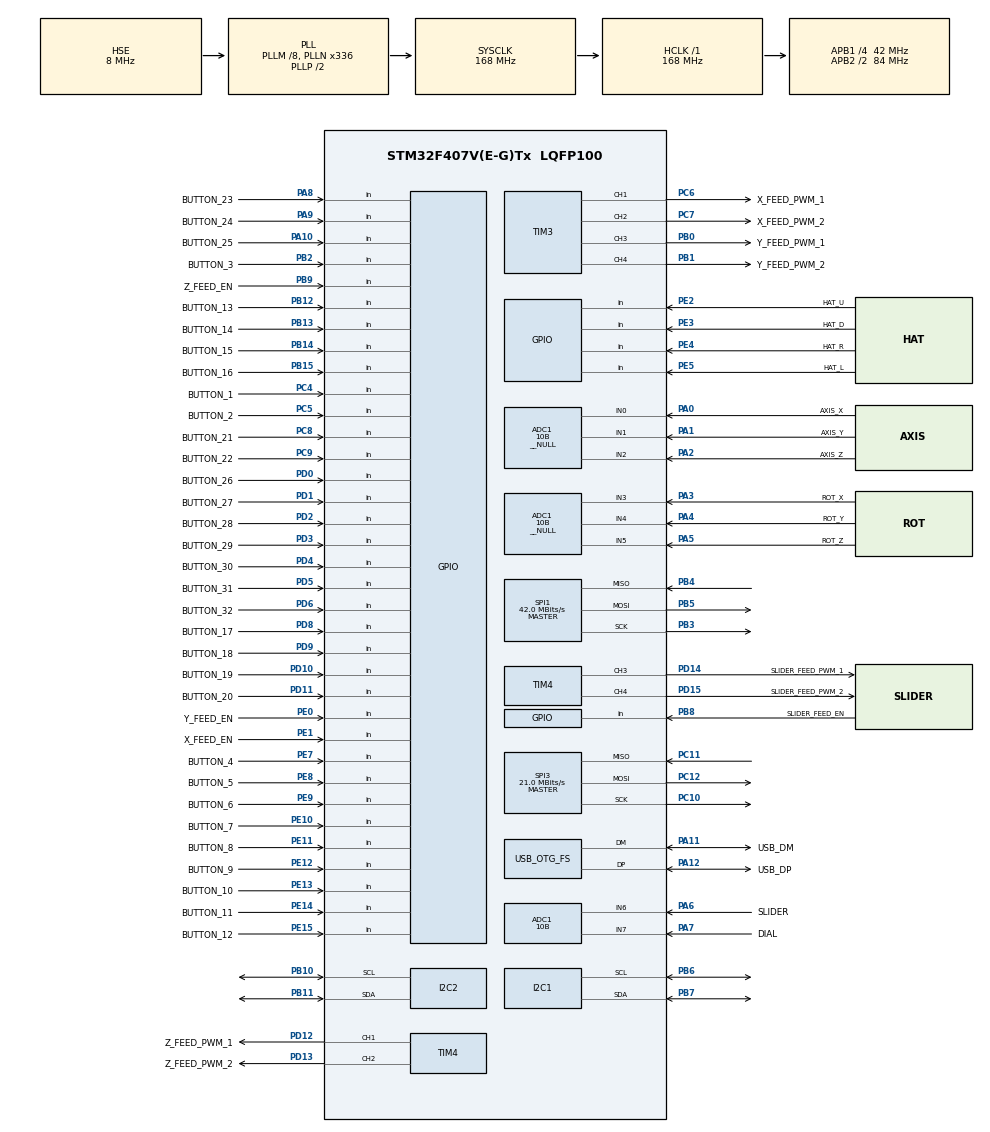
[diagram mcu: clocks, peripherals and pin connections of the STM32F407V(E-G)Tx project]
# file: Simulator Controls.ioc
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ADC1.Channel-0\#ChannelRegularConversion=ADC_CHANNEL_0
ADC1.Channel-1\#ChannelRegularConversion=ADC_CHANNEL_1
ADC1.Channel-2\#ChannelRegularConversion=ADC_CHANNEL_2
ADC1.Channel-3\#ChannelRegularConversion=ADC_CHANNEL_3
ADC1.Channel-4\#ChannelRegularConversion=ADC_CHANNEL_4
ADC1.Channel-5\#ChannelRegularConversion=ADC_CHANNEL_5
ADC1.Channel-6\#ChannelRegularConversion=ADC_CHANNEL_6
ADC1.Channel-7\#ChannelRegularConversion=ADC_CHANNEL_7
ADC1.ClockPrescaler=ADC_CLOCK_SYNC_PCLK_DIV4
ADC1.ContinuousConvMode=ENABLE
ADC1.DMAContinuousRequests=ENABLE
ADC1.DataAlign=ADC_DATAALIGN_RIGHT
ADC1.DiscontinuousConvMode=DISABLE
ADC1.EOCSelection=ADC_EOC_SEQ_CONV
ADC1.EnableAnalogWatchDog=false
ADC1.ExternalTrigConvEdge=ADC_EXTERNALTRIGCONVEDGE_NONE
ADC1.InjNumberOfConversion=0
ADC1.Mode=__NULL
ADC1.NbrOfConversion=8
ADC1.NbrOfConversionFlag=1
ADC1.Rank-0\#ChannelRegularConversion=1
ADC1.Rank-1\#ChannelRegularConversion=2
ADC1.Rank-2\#ChannelRegularConversion=3
ADC1.Rank-3\#ChannelRegularConversion=4
ADC1.Rank-4\#ChannelRegularConversion=5
ADC1.Rank-5\#ChannelRegularConversion=6
ADC1.Rank-6\#ChannelRegularConversion=7
ADC1.Rank-7\#ChannelRegularConversion=8
ADC1.Resolution=ADC_RESOLUTION_10B
ADC1.SamplingTime-0\#ChannelRegularConversion=ADC_SAMPLETIME_480CYCLES
ADC1.SamplingTime-1\#ChannelRegularConversion=ADC_SAMPLETIME_480CYCLES
ADC1.SamplingTime-2\#ChannelRegularConversion=ADC_SAMPLETIME_480CYCLES
ADC1.SamplingTime-3\#ChannelRegularConversion=ADC_SAMPLETIME_480CYCLES
ADC1.SamplingTime-4\#ChannelRegularConversion=ADC_SAMPLETIME_480CYCLES
ADC1.SamplingTime-5\#ChannelRegularConversion=ADC_SAMPLETIME_480CYCLES
ADC1.SamplingTime-6\#ChannelRegularConversion=ADC_SAMPLETIME_480CYCLES
ADC1.SamplingTime-7\#ChannelRegularConversion=ADC_SAMPLETIME_480CYCLES
ADC1.ScanConvMode=ENABLE
ADC1.master=1
Dma.ADC1.0.Direction=DMA_PERIPH_TO_MEMORY
Dma.ADC1.0.FIFOMode=DMA_FIFOMODE_DISABLE
Dma.ADC1.0.Instance=DMA2_Stream0
Dma.ADC1.0.MemDataAlignment=DMA_MDATAALIGN_WORD
Dma.ADC1.0.MemInc=DMA_MINC_ENABLE
Dma.ADC1.0.Mode=DMA_CIRCULAR
Dma.ADC1.0.PeriphDataAlignment=DMA_PDATAALIGN_WORD
Dma.ADC1.0.PeriphInc=DMA_PINC_DISABLE
Dma.ADC1.0.Priority=DMA_PRIORITY_LOW
Dma.Request0=ADC1
Mcu.Family=STM32F4
Mcu.Name=STM32F407V(E-G)Tx
Mcu.Package=LQFP100
NVIC.DMA2_Stream0_IRQn=true\:0\:0\:false\:false\:true
NVIC.OTG_FS_IRQn=true\:0\:0\:false\:false\:true
NVIC.PriorityGroup=NVIC_PRIORITYGROUP_4
PA0-WKUP.GPIO_Label=AXIS_X
PA0-WKUP.Signal=ADCx_IN0
PA1.GPIO_Label=AXIS_Y
PA1.Signal=ADCx_IN1
PA10.GPIO_Label=BUTTON_25
PA10.GPIO_Mode=GPIO_MODE_INPUT
PA10.GPIO_PuPd=GPIO_PULLDOWN
PA10.Signal=GPIO_Input
PA11.GPIO_Label=USB_DM
PA11.Mode=Device_Only
PA11.Signal=USB_OTG_FS_DM
PA12.GPIO_Label=USB_DP
PA12.Mode=Device_Only
PA12.Signal=USB_OTG_FS_DP
PA13.GPIO_Label=SWDIO
PA13.Mode=Serial_Wire
PA13.Signal=SYS_JTMS-SWDIO
PA14.GPIO_Label=SWCLK
PA14.Mode=Serial_Wire
PA14.Signal=SYS_JTCK-SWCLK
PA2.GPIO_Label=AXIS_Z
PA2.Signal=ADCx_IN2
PA3.GPIO_Label=ROT_X
PA3.Signal=ADCx_IN3
PA4.GPIO_Label=ROT_Y
PA4.Signal=ADCx_IN4
PA5.GPIO_Label=ROT_Z
PA5.Signal=ADCx_IN5
PA6.GPIO_Label=SLIDER
PA6.Signal=ADCx_IN6
PA7.GPIO_Label=DIAL
PA7.Signal=ADCx_IN7
PA8.GPIO_Label=BUTTON_23
PA8.GPIO_Mode=GPIO_MODE_INPUT
PA8.GPIO_PuPd=GPIO_PULLDOWN
PA8.Signal=GPIO_Input
PA9.GPIO_Label=BUTTON_24
PA9.GPIO_Mode=GPIO_MODE_INPUT
PA9.GPIO_PuPd=GPIO_PULLDOWN
PA9.Signal=GPIO_Input
PB0.GPIO_Label=Y_FEED_PWM_1
PB0.Signal=S_TIM3_CH3
PB1.GPIO_Label=Y_FEED_PWM_2
PB1.Signal=S_TIM3_CH4
PB10.Mode=I2C
PB10.Signal=I2C2_SCL
PB11.Mode=I2C
PB11.Signal=I2C2_SDA
PB12.GPIO_Label=BUTTON_13
PB12.GPIO_Mode=GPIO_MODE_INPUT
PB12.GPIO_PuPd=GPIO_PULLDOWN
PB12.Signal=GPIO_Input
PB13.GPIO_Label=BUTTON_14
PB13.GPIO_Mode=GPIO_MODE_INPUT
PB13.GPIO_PuPd=GPIO_PULLDOWN
PB13.Signal=GPIO_Input
PB14.GPIO_Label=BUTTON_15
PB14.GPIO_Mode=GPIO_MODE_INPUT
PB14.GPIO_PuPd=GPIO_PULLDOWN
PB14.Signal=GPIO_Input
PB15.GPIO_Label=BUTTON_16
PB15.GPIO_Mode=GPIO_MODE_INPUT
PB15.GPIO_PuPd=GPIO_PULLDOWN
PB15.Signal=GPIO_Input
PB2.GPIO_Label=BUTTON_3
PB2.GPIO_Mode=GPIO_MODE_INPUT
PB2.GPIO_PuPd=GPIO_PULLDOWN
PB2.Signal=GPIO_Input
PB3.Mode=Full_Duplex_Master
PB3.Signal=SPI1_SCK
PB4.Mode=Full_Duplex_Master
PB4.Signal=SPI1_MISO
PB5.Mode=Full_Duplex_Master
PB5.Signal=SPI1_MOSI
PB6.Mode=I2C
PB6.Signal=I2C1_SCL
PB7.Mode=I2C
PB7.Signal=I2C1_SDA
PB8.GPIO_Label=SLIDER_FEED_EN
PB8.GPIO_Mode=GPIO_MODE_INPUT
PB8.GPIO_PuPd=GPIO_PULLDOWN
PB8.Signal=GPIO_Input
PB9.GPIO_Label=Z_FEED_EN
PB9.GPIO_Mode=GPIO_MODE_INPUT
PB9.GPIO_PuPd=GPIO_PULLDOWN
PB9.Signal=GPIO_Input
PC10.Mode=Full_Duplex_Master
PC10.Signal=SPI3_SCK
PC11.Mode=Full_Duplex_Master
PC11.Signal=SPI3_MISO
PC12.Mode=Full_Duplex_Master
PC12.Signal=SPI3_MOSI
PC4.GPIO_Label=BUTTON_1
PC4.GPIO_Mode=GPIO_MODE_INPUT
PC4.GPIO_PuPd=GPIO_PULLDOWN
PC4.Signal=GPIO_Input
PC5.GPIO_Label=BUTTON_2
PC5.GPIO_Mode=GPIO_MODE_INPUT
PC5.GPIO_PuPd=GPIO_PULLDOWN
PC5.Signal=GPIO_Input
PC6.GPIO_Label=X_FEED_PWM_1
PC6.Signal=S_TIM3_CH1
PC7.GPIO_Label=X_FEED_PWM_2
PC7.Signal=S_TIM3_CH2
PC8.GPIO_Label=BUTTON_21
PC8.GPIO_Mode=GPIO_MODE_INPUT
PC8.GPIO_PuPd=GPIO_PULLDOWN
PC8.Signal=GPIO_Input
PC9.GPIO_Label=BUTTON_22
PC9.GPIO_Mode=GPIO_MODE_INPUT
PC9.GPIO_PuPd=GPIO_PULLDOWN
PC9.Signal=GPIO_Input
PD0.GPIO_Label=BUTTON_26
PD0.GPIO_Mode=GPIO_MODE_INPUT
PD0.GPIO_PuPd=GPIO_PULLDOWN
PD0.Signal=GPIO_Input
PD1.GPIO_Label=BUTTON_27
PD1.GPIO_Mode=GPIO_MODE_INPUT
PD1.GPIO_PuPd=GPIO_PULLDOWN
PD1.Signal=GPIO_Input
PD10.GPIO_Label=BUTTON_19
PD10.GPIO_Mode=GPIO_MODE_INPUT
PD10.GPIO_PuPd=GPIO_PULLDOWN
PD10.Signal=GPIO_Input
PD11.GPIO_Label=BUTTON_20
PD11.GPIO_Mode=GPIO_MODE_INPUT
PD11.GPIO_PuPd=GPIO_PULLDOWN
PD11.Signal=GPIO_Input
PD12.GPIO_Label=Z_FEED_PWM_1
PD12.Signal=S_TIM4_CH1
PD13.GPIO_Label=Z_FEED_PWM_2
PD13.Signal=S_TIM4_CH2
PD14.GPIO_Label=SLIDER_FEED_PWM_1
PD14.Signal=S_TIM4_CH3
PD15.GPIO_Label=SLIDER_FEED_PWM_2
PD15.Signal=S_TIM4_CH4
PD2.GPIO_Label=BUTTON_28
PD2.GPIO_Mode=GPIO_MODE_INPUT
PD2.GPIO_PuPd=GPIO_PULLDOWN
PD2.Signal=GPIO_Input
PD3.GPIO_Label=BUTTON_29
PD3.GPIO_Mode=GPIO_MODE_INPUT
PD3.GPIO_PuPd=GPIO_PULLDOWN
PD3.Signal=GPIO_Input
PD4.GPIO_Label=BUTTON_30
PD4.GPIO_Mode=GPIO_MODE_INPUT
PD4.GPIO_PuPd=GPIO_PULLDOWN
PD4.Signal=GPIO_Input
PD5.GPIO_Label=BUTTON_31
PD5.GPIO_Mode=GPIO_MODE_INPUT
PD5.GPIO_PuPd=GPIO_PULLDOWN
PD5.Signal=GPIO_Input
PD6.GPIO_Label=BUTTON_32
PD6.GPIO_Mode=GPIO_MODE_INPUT
PD6.GPIO_PuPd=GPIO_PULLDOWN
PD6.Signal=GPIO_Input
PD8.GPIO_Label=BUTTON_17
PD8.GPIO_Mode=GPIO_MODE_INPUT
PD8.GPIO_PuPd=GPIO_PULLDOWN
PD8.Signal=GPIO_Input
PD9.GPIO_Label=BUTTON_18
PD9.GPIO_Mode=GPIO_MODE_INPUT
PD9.GPIO_PuPd=GPIO_PULLDOWN
PD9.Signal=GPIO_Input
PE0.GPIO_Label=Y_FEED_EN
PE0.GPIO_Mode=GPIO_MODE_INPUT
PE0.GPIO_PuPd=GPIO_PULLDOWN
PE0.Signal=GPIO_Input
PE1.GPIO_Label=X_FEED_EN
PE1.GPIO_Mode=GPIO_MODE_INPUT
PE1.GPIO_PuPd=GPIO_PULLDOWN
PE1.Signal=GPIO_Input
PE10.GPIO_Label=BUTTON_7
PE10.GPIO_Mode=GPIO_MODE_INPUT
PE10.GPIO_PuPd=GPIO_PULLDOWN
PE10.Signal=GPIO_Input
PE11.GPIO_Label=BUTTON_8
PE11.GPIO_Mode=GPIO_MODE_INPUT
PE11.GPIO_PuPd=GPIO_PULLDOWN
PE11.Signal=GPIO_Input
PE12.GPIO_Label=BUTTON_9
PE12.GPIO_Mode=GPIO_MODE_INPUT
PE12.GPIO_PuPd=GPIO_PULLDOWN
PE12.Signal=GPIO_Input
PE13.GPIO_Label=BUTTON_10
PE13.GPIO_Mode=GPIO_MODE_INPUT
PE13.GPIO_PuPd=GPIO_PULLDOWN
PE13.Signal=GPIO_Input
PE14.GPIO_Label=BUTTON_11
PE14.GPIO_Mode=GPIO_MODE_INPUT
PE14.GPIO_PuPd=GPIO_PULLDOWN
PE14.Signal=GPIO_Input
PE15.GPIO_Label=BUTTON_12
PE15.GPIO_Mode=GPIO_MODE_INPUT
PE15.GPIO_PuPd=GPIO_PULLDOWN
PE15.Signal=GPIO_Input
PE2.GPIO_Label=HAT_U
PE2.GPIO_Mode=GPIO_MODE_INPUT
PE2.GPIO_PuPd=GPIO_PULLDOWN
PE2.Signal=GPIO_Input
PE3.GPIO_Label=HAT_D
PE3.GPIO_Mode=GPIO_MODE_INPUT
PE3.GPIO_PuPd=GPIO_PULLDOWN
PE3.Signal=GPIO_Input
PE4.GPIO_Label=HAT_R
PE4.GPIO_Mode=GPIO_MODE_INPUT
PE4.GPIO_PuPd=GPIO_PULLDOWN
PE4.Signal=GPIO_Input
PE5.GPIO_Label=HAT_L
PE5.GPIO_Mode=GPIO_MODE_INPUT
PE5.GPIO_PuPd=GPIO_PULLDOWN
PE5.Signal=GPIO_Input
PE7.GPIO_Label=BUTTON_4
PE7.GPIO_Mode=GPIO_MODE_INPUT
PE7.GPIO_PuPd=GPIO_PULLDOWN
PE7.Signal=GPIO_Input
PE8.GPIO_Label=BUTTON_5
PE8.GPIO_Mode=GPIO_MODE_INPUT
PE8.GPIO_PuPd=GPIO_PULLDOWN
PE8.Signal=GPIO_Input
PE9.GPIO_Label=BUTTON_6
PE9.GPIO_Mode=GPIO_MODE_INPUT
PE9.GPIO_PuPd=GPIO_PULLDOWN
PE9.Signal=GPIO_Input
PH0-OSC_IN.Mode=HSE-External-Oscillator
PH0-OSC_IN.Signal=RCC_OSC_IN
PH1-OSC_OUT.Mode=HSE-External-Oscillator
PH1-OSC_OUT.Signal=RCC_OSC_OUT
ProjectManager.HeapSize=0x200
ProjectManager.StackSize=0x400
ProjectManager.TargetToolchain=MDK-ARM V5
RCC.48MHZClocksFreq_Value=48000000
RCC.AHBFreq_Value=168000000
RCC.APB1CLKDivider=RCC_HCLK_DIV4
RCC.APB1Freq_Value=42000000
RCC.APB1TimFreq_Value=84000000
RCC.APB2CLKDivider=RCC_HCLK_DIV2
RCC.APB2Freq_Value=84000000
RCC.APB2TimFreq_Value=168000000
RCC.CortexFreq_Value=168000000
RCC.HCLKFreq_Value=168000000
RCC.HSE_VALUE=8000000
RCC.HSI_VALUE=16000000
RCC.LSE_VALUE=32768
RCC.PLLM=8
RCC.PLLN=336
RCC.PLLQ=7
RCC.SYSCLKFreq_VALUE=168000000
RCC.SYSCLKSource=RCC_SYSCLKSOURCE_PLLCLK
RCC.VCOOutputFreq_Value=336000000
SH.ADCx_IN0.0=ADC1_IN0,IN0
SH.ADCx_IN1.0=ADC1_IN1,IN1
SH.ADCx_IN2.0=ADC1_IN2,IN2
SH.ADCx_IN3.0=ADC1_IN3,IN3
SH.ADCx_IN4.0=ADC1_IN4,IN4
SH.ADCx_IN5.0=ADC1_IN5,IN5
SH.ADCx_IN6.0=ADC1_IN6,IN6
SH.ADCx_IN7.0=ADC1_IN7,IN7
SH.S_TIM3_CH1.0=TIM3_CH1,PWM Generation1 CH1
SH.S_TIM3_CH2.0=TIM3_CH2,PWM Generation2 CH2
SH.S_TIM3_CH3.0=TIM3_CH3,PWM Generation3 CH3
SH.S_TIM3_CH4.0=TIM3_CH4,PWM Generation4 CH4
SH.S_TIM4_CH1.0=TIM4_CH1,PWM Generation1 CH1
SH.S_TIM4_CH2.0=TIM4_CH2,Output Compare2 CH2
SH.S_TIM4_CH3.0=TIM4_CH3,PWM Generation3 CH3
SH.S_TIM4_CH4.0=TIM4_CH4,PWM Generation4 CH4
SPI1.BaudRatePrescaler=SPI_BAUDRATEPRESCALER_2
SPI1.CalculateBaudRate=42.0 MBits/s
SPI1.Mode=SPI_MODE_MASTER
SPI3.CalculateBaudRate=21.0 MBits/s
SPI3.Mode=SPI_MODE_MASTER
TIM3.Channel-PWM\ Generation2\ CH2=TIM_CHANNEL_2
TIM3.Channel-PWM\ Generation3\ CH3=TIM_CHANNEL_3
TIM3.Channel-PWM\ Generation4\ CH4=TIM_CHANNEL_4
TIM4.Channel-Output\ Compare2\ CH2=TIM_CHANNEL_2
TIM4.Channel-PWM\ Generation3\ CH3=TIM_CHANNEL_3
TIM4.Channel-PWM\ Generation4\ CH4=TIM_CHANNEL_4
USB_DEVICE.CLASS_NAME-CUSTOM_HID_FS=CUSTOMHID
USB_DEVICE.PRODUCT_STRING_CUSTOMHID_FS=Simulator Controls
USB_DEVICE.USBD_CUSTOMHID_OUTREPORT_BUF_SIZE-CUSTOM_HID_FS=2
USB_DEVICE.USBD_CUSTOM_HID_REPORT_DESC_SIZE-CUSTOM_HID_FS=86
USB_DEVICE.USBD_HandleTypeDef-CUSTOM_HID_FS=hUsbDeviceFS
USB_DEVICE.VirtualMode-CUSTOM_HID_FS=CustomHid
USB_DEVICE.VirtualModeFS=Custom_Hid_FS
USB_OTG_FS.VirtualMode=Device_Only
USB_OTG_FS.vbus_sensing_enable=DISABLE
VP_TIM3_VS_ClockSourceINT.Mode=Internal
VP_TIM4_VS_ClockSourceINT.Mode=Internal
VP_USB_DEVICE_VS_USB_DEVICE_CUSTOM_HID_FS.Mode=CUSTOM_HID_FS
board=Simulator Controls

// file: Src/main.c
/**
  ******************************************************************************
  * File Name          : main.c
  * Description        : Main program body
  ******************************************************************************
  *
  * Copyright (c) 2016 STMicroelectronics International N.V.
  * All rights reserved.
  *
  * Redistribution and use in source and binary forms, with or without
  * modification, are permitted, provided that the following conditions are met:
  *
  * 1. Redistribution of source code must retain the above copyright notice,
  *    this list of conditions and the following disclaimer.
  * 2. Redistributions in binary form must reproduce the above copyright notice,
  *    this list of conditions and the following disclaimer in the documentation
  *    and/or other materials provided with the distribution.
  * 3. Neither the name of STMicroelectronics nor the names of other
  *    contributors to this software may be used to endorse or promote products
  *    derived from this software without specific written permission.
  * 4. This software, including modifications and/or derivative works of this
  *    software, must execute solely and exclusively on microcontroller or
  *    microprocessor devices manufactured by or for STMicroelectronics.
  * 5. Redistribution and use of this software other than as permitted under
  *    this license is void and will automatically terminate your rights under
  *    this license.
  *
  * THIS SOFTWARE IS PROVIDED BY STMICROELECTRONICS AND CONTRIBUTORS "AS IS"
  * AND ANY EXPRESS, IMPLIED OR STATUTORY WARRANTIES, INCLUDING, BUT NOT
  * LIMITED TO, THE IMPLIED WARRANTIES OF MERCHANTABILITY, FITNESS FOR A
  * PARTICULAR PURPOSE AND NON-INFRINGEMENT OF THIRD PARTY INTELLECTUAL PROPERTY
  * RIGHTS ARE DISCLAIMED TO THE FULLEST EXTENT PERMITTED BY LAW. IN NO EVENT
  * SHALL STMICROELECTRONICS OR CONTRIBUTORS BE LIABLE FOR ANY DIRECT, INDIRECT,
  * INCIDENTAL, SPECIAL, EXEMPLARY, OR CONSEQUENTIAL DAMAGES (INCLUDING, BUT NOT
  * LIMITED TO, PROCUREMENT OF SUBSTITUTE GOODS OR SERVICES; LOSS OF USE, DATA,
  * OR PROFITS; OR BUSINESS INTERRUPTION) HOWEVER CAUSED AND ON ANY THEORY OF
  * LIABILITY, WHETHER IN CONTRACT, STRICT LIABILITY, OR TORT (INCLUDING
  * NEGLIGENCE OR OTHERWISE) ARISING IN ANY WAY OUT OF THE USE OF THIS SOFTWARE,
  * EVEN IF ADVISED OF THE POSSIBILITY OF SUCH DAMAGE.
  *
  ******************************************************************************
  */
#include "main.h"
#include "stm32f4xx_hal.h"
#include "usb_device.h"

/* USER CODE BEGIN Includes */
#include "simCon.h"
/* USER CODE END Includes */

ADC_HandleTypeDef hadc1;
DMA_HandleTypeDef hdma_adc1;

I2C_HandleTypeDef hi2c1;
I2C_HandleTypeDef hi2c2;

SPI_HandleTypeDef hspi1;
SPI_HandleTypeDef hspi3;

TIM_HandleTypeDef htim3;
TIM_HandleTypeDef htim4;

/* USER CODE BEGIN PV */
/* Private variables ---------------------------------------------------------*/

/* USER CODE END PV */

void SystemClock_Config(void);
void Error_Handler(void);
static void MX_GPIO_Init(void);
static void MX_DMA_Init(void);
static void MX_ADC1_Init(void);
static void MX_I2C1_Init(void);
static void MX_I2C2_Init(void);
static void MX_SPI1_Init(void);
static void MX_SPI3_Init(void);
static void MX_TIM3_Init(void);
static void MX_TIM4_Init(void);

void HAL_TIM_MspPostInit(TIM_HandleTypeDef *htim);

/* USER CODE BEGIN PFP */
/* Private function prototypes -----------------------------------------------*/

/* USER CODE END PFP */

int main(void)
{

  /* MCU Configuration----------------------------------------------------------*/

  /* Reset of all peripherals, Initializes the Flash interface and the Systick. */
  HAL_Init();

  /* Configure the system clock */
  SystemClock_Config();

  /* Initialize all configured peripherals */
  MX_GPIO_Init();
  MX_DMA_Init();
  MX_USB_DEVICE_Init();
  MX_ADC1_Init();
  MX_I2C1_Init();
  MX_I2C2_Init();
  MX_SPI1_Init();
  MX_SPI3_Init();
  MX_TIM3_Init();
  MX_TIM4_Init();

  /* USER CODE BEGIN 2 */
	simCon_init();
  /* USER CODE END 2 */

  /* Infinite loop */
  while (1)
  {

  }

}

/** System Clock Configuration
*/
void SystemClock_Config(void)
{

  RCC_OscInitTypeDef RCC_OscInitStruct;
  RCC_ClkInitTypeDef RCC_ClkInitStruct;

    /**Configure the main internal regulator output voltage
    */
  __HAL_RCC_PWR_CLK_ENABLE();

  __HAL_PWR_VOLTAGESCALING_CONFIG(PWR_REGULATOR_VOLTAGE_SCALE1);

    /**Initializes the CPU, AHB and APB busses clocks
    */
  RCC_OscInitStruct.OscillatorType = RCC_OSCILLATORTYPE_HSE;
  RCC_OscInitStruct.HSEState = RCC_HSE_ON;
  RCC_OscInitStruct.PLL.PLLState = RCC_PLL_ON;
  RCC_OscInitStruct.PLL.PLLSource = RCC_PLLSOURCE_HSE;
  RCC_OscInitStruct.PLL.PLLM = 8;
  RCC_OscInitStruct.PLL.PLLN = 336;
  RCC_OscInitStruct.PLL.PLLP = RCC_PLLP_DIV2;
  RCC_OscInitStruct.PLL.PLLQ = 7;
  if (HAL_RCC_OscConfig(&RCC_OscInitStruct) != HAL_OK)
  {
    Error_Handler();
  }

    /**Initializes the CPU, AHB and APB busses clocks
    */
  RCC_ClkInitStruct.ClockType = RCC_CLOCKTYPE_HCLK|RCC_CLOCKTYPE_SYSCLK
                              |RCC_CLOCKTYPE_PCLK1|RCC_CLOCKTYPE_PCLK2;
  RCC_ClkInitStruct.SYSCLKSource = RCC_SYSCLKSOURCE_PLLCLK;
  RCC_ClkInitStruct.AHBCLKDivider = RCC_SYSCLK_DIV1;
  RCC_ClkInitStruct.APB1CLKDivider = RCC_HCLK_DIV4;
  RCC_ClkInitStruct.APB2CLKDivider = RCC_HCLK_DIV2;

  if (HAL_RCC_ClockConfig(&RCC_ClkInitStruct, FLASH_LATENCY_5) != HAL_OK)
  {
    Error_Handler();
  }

    /**Configure the Systick interrupt time
    */
  HAL_SYSTICK_Config(HAL_RCC_GetHCLKFreq()/1000);

    /**Configure the Systick
    */
  HAL_SYSTICK_CLKSourceConfig(SYSTICK_CLKSOURCE_HCLK);

  /* SysTick_IRQn interrupt configuration */
  HAL_NVIC_SetPriority(SysTick_IRQn, 0, 0);
}

/* ADC1 init function */
static void MX_ADC1_Init(void)
{

  ADC_ChannelConfTypeDef sConfig;

    /**Configure the global features of the ADC (Clock, Resolution, Data Alignment and number of conversion)
    */
  hadc1.Instance = ADC1;
  hadc1.Init.ClockPrescaler = ADC_CLOCK_SYNC_PCLK_DIV4;
  hadc1.Init.Resolution = ADC_RESOLUTION_10B;
  hadc1.Init.ScanConvMode = ENABLE;
  hadc1.Init.ContinuousConvMode = ENABLE;
  hadc1.Init.DiscontinuousConvMode = DISABLE;
  hadc1.Init.ExternalTrigConvEdge = ADC_EXTERNALTRIGCONVEDGE_NONE;
  hadc1.Init.DataAlign = ADC_DATAALIGN_RIGHT;
  hadc1.Init.NbrOfConversion = 8;
  hadc1.Init.DMAContinuousRequests = ENABLE;
  hadc1.Init.EOCSelection = ADC_EOC_SEQ_CONV;
  if (HAL_ADC_Init(&hadc1) != HAL_OK)
  {
    Error_Handler();
  }

    /**Configure for the selected ADC regular channel its corresponding rank in the sequencer and its sample time.
    */
  sConfig.Channel = ADC_CHANNEL_0;
  sConfig.Rank = 1;
  sConfig.SamplingTime = ADC_SAMPLETIME_480CYCLES;
  if (HAL_ADC_ConfigChannel(&hadc1, &sConfig) != HAL_OK)
  {
    Error_Handler();
  }

    /**Configure for the selected ADC regular channel its corresponding rank in the sequencer and its sample time.
    */
  sConfig.Channel = ADC_CHANNEL_1;
  sConfig.Rank = 2;
  if (HAL_ADC_ConfigChannel(&hadc1, &sConfig) != HAL_OK)
  {
    Error_Handler();
  }

    /**Configure for the selected ADC regular channel its corresponding rank in the sequencer and its sample time.
    */
  sConfig.Channel = ADC_CHANNEL_2;
  sConfig.Rank = 3;
  if (HAL_ADC_ConfigChannel(&hadc1, &sConfig) != HAL_OK)
  {
    Error_Handler();
  }

    /**Configure for the selected ADC regular channel its corresponding rank in the sequencer and its sample time.
    */
  sConfig.Channel = ADC_CHANNEL_3;
  sConfig.Rank = 4;
  if (HAL_ADC_ConfigChannel(&hadc1, &sConfig) != HAL_OK)
  {
    Error_Handler();
  }

    /**Configure for the selected ADC regular channel its corresponding rank in the sequencer and its sample time.
    */
  sConfig.Channel = ADC_CHANNEL_4;
  sConfig.Rank = 5;
  if (HAL_ADC_ConfigChannel(&hadc1, &sConfig) != HAL_OK)
  {
    Error_Handler();
  }

    /**Configure for the selected ADC regular channel its corresponding rank in the sequencer and its sample time.
    */
  sConfig.Channel = ADC_CHANNEL_5;
  sConfig.Rank = 6;
  if (HAL_ADC_ConfigChannel(&hadc1, &sConfig) != HAL_OK)
  {
    Error_Handler();
  }

    /**Configure for the selected ADC regular channel its corresponding rank in the sequencer and its sample time.
    */
  sConfig.Channel = ADC_CHANNEL_6;
  sConfig.Rank = 7;
  if (HAL_ADC_ConfigChannel(&hadc1, &sConfig) != HAL_OK)
  {
    Error_Handler();
  }

    /**Configure for the selected ADC regular channel its corresponding rank in the sequencer and its sample time.
    */
  sConfig.Channel = ADC_CHANNEL_7;
  sConfig.Rank = 8;
  if (HAL_ADC_ConfigChannel(&hadc1, &sConfig) != HAL_OK)
  {
    Error_Handler();
  }

}

/* I2C1 init function */
static void MX_I2C1_Init(void)
{

  hi2c1.Instance = I2C1;
  hi2c1.Init.ClockSpeed = 100000;
  hi2c1.Init.DutyCycle = I2C_DUTYCYCLE_2;
  hi2c1.Init.OwnAddress1 = 0;
  hi2c1.Init.AddressingMode = I2C_ADDRESSINGMODE_7BIT;
  hi2c1.Init.DualAddressMode = I2C_DUALADDRESS_DISABLE;
  hi2c1.Init.OwnAddress2 = 0;
  hi2c1.Init.GeneralCallMode = I2C_GENERALCALL_DISABLE;
  hi2c1.Init.NoStretchMode = I2C_NOSTRETCH_DISABLE;
  if (HAL_I2C_Init(&hi2c1) != HAL_OK)
  {
    Error_Handler();
  }

}

/* I2C2 init function */
static void MX_I2C2_Init(void)
{

  hi2c2.Instance = I2C2;
  hi2c2.Init.ClockSpeed = 100000;
  hi2c2.Init.DutyCycle = I2C_DUTYCYCLE_2;
  hi2c2.Init.OwnAddress1 = 0;
  hi2c2.Init.AddressingMode = I2C_ADDRESSINGMODE_7BIT;
  hi2c2.Init.DualAddressMode = I2C_DUALADDRESS_DISABLE;
  hi2c2.Init.OwnAddress2 = 0;
  hi2c2.Init.GeneralCallMode = I2C_GENERALCALL_DISABLE;
  hi2c2.Init.NoStretchMode = I2C_NOSTRETCH_DISABLE;
  if (HAL_I2C_Init(&hi2c2) != HAL_OK)
  {
    Error_Handler();
  }

}

/* SPI1 init function */
static void MX_SPI1_Init(void)
{

  hspi1.Instance = SPI1;
  hspi1.Init.Mode = SPI_MODE_MASTER;
  hspi1.Init.Direction = SPI_DIRECTION_2LINES;
  hspi1.Init.DataSize = SPI_DATASIZE_8BIT;
  hspi1.Init.CLKPolarity = SPI_POLARITY_LOW;
  hspi1.Init.CLKPhase = SPI_PHASE_1EDGE;
  hspi1.Init.NSS = SPI_NSS_SOFT;
  hspi1.Init.BaudRatePrescaler = SPI_BAUDRATEPRESCALER_2;
  hspi1.Init.FirstBit = SPI_FIRSTBIT_MSB;
  hspi1.Init.TIMode = SPI_TIMODE_DISABLE;
  hspi1.Init.CRCCalculation = SPI_CRCCALCULATION_DISABLE;
  hspi1.Init.CRCPolynomial = 10;
  if (HAL_SPI_Init(&hspi1) != HAL_OK)
  {
    Error_Handler();
  }

}

/* SPI3 init function */
static void MX_SPI3_Init(void)
{

  hspi3.Instance = SPI3;
  hspi3.Init.Mode = SPI_MODE_MASTER;
  hspi3.Init.Direction = SPI_DIRECTION_2LINES;
  hspi3.Init.DataSize = SPI_DATASIZE_8BIT;
  hspi3.Init.CLKPolarity = SPI_POLARITY_LOW;
  hspi3.Init.CLKPhase = SPI_PHASE_1EDGE;
  hspi3.Init.NSS = SPI_NSS_SOFT;
  hspi3.Init.BaudRatePrescaler = SPI_BAUDRATEPRESCALER_2;
  hspi3.Init.FirstBit = SPI_FIRSTBIT_MSB;
  hspi3.Init.TIMode = SPI_TIMODE_DISABLE;
  hspi3.Init.CRCCalculation = SPI_CRCCALCULATION_DISABLE;
  hspi3.Init.CRCPolynomial = 10;
  if (HAL_SPI_Init(&hspi3) != HAL_OK)
  {
    Error_Handler();
  }

}

/* TIM3 init function */
static void MX_TIM3_Init(void)
{

  TIM_ClockConfigTypeDef sClockSourceConfig;
  TIM_MasterConfigTypeDef sMasterConfig;
  TIM_OC_InitTypeDef sConfigOC;

  htim3.Instance = TIM3;
  htim3.Init.Prescaler = 0;
  htim3.Init.CounterMode = TIM_COUNTERMODE_UP;
  htim3.Init.Period = 0;
  htim3.Init.ClockDivision = TIM_CLOCKDIVISION_DIV1;
  if (HAL_TIM_Base_Init(&htim3) != HAL_OK)
  {
    Error_Handler();
  }

  sClockSourceConfig.ClockSource = TIM_CLOCKSOURCE_INTERNAL;
  if (HAL_TIM_ConfigClockSource(&htim3, &sClockSourceConfig) != HAL_OK)
  {
    Error_Handler();
  }

  if (HAL_TIM_PWM_Init(&htim3) != HAL_OK)
  {
    Error_Handler();
  }

  sMasterConfig.MasterOutputTrigger = TIM_TRGO_RESET;
  sMasterConfig.MasterSlaveMode = TIM_MASTERSLAVEMODE_DISABLE;
  if (HAL_TIMEx_MasterConfigSynchronization(&htim3, &sMasterConfig) != HAL_OK)
  {
    Error_Handler();
  }

  sConfigOC.OCMode = TIM_OCMODE_PWM1;
  sConfigOC.Pulse = 0;
  sConfigOC.OCPolarity = TIM_OCPOLARITY_HIGH;
  sConfigOC.OCFastMode = TIM_OCFAST_DISABLE;
  if (HAL_TIM_PWM_ConfigChannel(&htim3, &sConfigOC, TIM_CHANNEL_1) != HAL_OK)
  {
    Error_Handler();
  }

  if (HAL_TIM_PWM_ConfigChannel(&htim3, &sConfigOC, TIM_CHANNEL_2) != HAL_OK)
  {
    Error_Handler();
  }

  if (HAL_TIM_PWM_ConfigChannel(&htim3, &sConfigOC, TIM_CHANNEL_3) != HAL_OK)
  {
    Error_Handler();
  }

  if (HAL_TIM_PWM_ConfigChannel(&htim3, &sConfigOC, TIM_CHANNEL_4) != HAL_OK)
  {
    Error_Handler();
  }

  HAL_TIM_MspPostInit(&htim3);

}

/* TIM4 init function */
static void MX_TIM4_Init(void)
{

  TIM_ClockConfigTypeDef sClockSourceConfig;
  TIM_MasterConfigTypeDef sMasterConfig;
  TIM_OC_InitTypeDef sConfigOC;

  htim4.Instance = TIM4;
  htim4.Init.Prescaler = 0;
  htim4.Init.CounterMode = TIM_COUNTERMODE_UP;
  htim4.Init.Period = 0;
  htim4.Init.ClockDivision = TIM_CLOCKDIVISION_DIV1;
  if (HAL_TIM_Base_Init(&htim4) != HAL_OK)
  {
    Error_Handler();
  }

  sClockSourceConfig.ClockSource = TIM_CLOCKSOURCE_INTERNAL;
  if (HAL_TIM_ConfigClockSource(&htim4, &sClockSourceConfig) != HAL_OK)
  {
    Error_Handler();
  }

  if (HAL_TIM_PWM_Init(&htim4) != HAL_OK)
  {
    Error_Handler();
  }

  if (HAL_TIM_OC_Init(&htim4) != HAL_OK)
  {
    Error_Handler();
  }

  sMasterConfig.MasterOutputTrigger = TIM_TRGO_RESET;
  sMasterConfig.MasterSlaveMode = TIM_MASTERSLAVEMODE_DISABLE;
  if (HAL_TIMEx_MasterConfigSynchronization(&htim4, &sMasterConfig) != HAL_OK)
  {
    Error_Handler();
  }

  sConfigOC.OCMode = TIM_OCMODE_PWM1;
  sConfigOC.Pulse = 0;
  sConfigOC.OCPolarity = TIM_OCPOLARITY_HIGH;
  sConfigOC.OCFastMode = TIM_OCFAST_DISABLE;
  if (HAL_TIM_PWM_ConfigChannel(&htim4, &sConfigOC, TIM_CHANNEL_1) != HAL_OK)
  {
    Error_Handler();
  }

  sConfigOC.OCMode = TIM_OCMODE_TIMING;
  if (HAL_TIM_OC_ConfigChannel(&htim4, &sConfigOC, TIM_CHANNEL_2) != HAL_OK)
  {
    Error_Handler();
  }

  sConfigOC.OCMode = TIM_OCMODE_PWM1;
  if (HAL_TIM_PWM_ConfigChannel(&htim4, &sConfigOC, TIM_CHANNEL_3) != HAL_OK)
  {
    Error_Handler();
  }

  if (HAL_TIM_PWM_ConfigChannel(&htim4, &sConfigOC, TIM_CHANNEL_4) != HAL_OK)
  {
    Error_Handler();
  }

  HAL_TIM_MspPostInit(&htim4);

}

static void MX_DMA_Init(void)
{
  /* DMA controller clock enable */
  __HAL_RCC_DMA2_CLK_ENABLE();

  /* DMA interrupt init */
  /* DMA2_Stream0_IRQn interrupt configuration */
  HAL_NVIC_SetPriority(DMA2_Stream0_IRQn, 0, 0);
  HAL_NVIC_EnableIRQ(DMA2_Stream0_IRQn);

}

/** Configure pins as
        * Analog
        * Input
        * Output
        * EVENT_OUT
        * EXTI
*/
static void MX_GPIO_Init(void)
{

  GPIO_InitTypeDef GPIO_InitStruct;

  /* GPIO Ports Clock Enable */
  __HAL_RCC_GPIOE_CLK_ENABLE();
  __HAL_RCC_GPIOH_CLK_ENABLE();
  __HAL_RCC_GPIOA_CLK_ENABLE();
  __HAL_RCC_GPIOC_CLK_ENABLE();
  __HAL_RCC_GPIOB_CLK_ENABLE();
  __HAL_RCC_GPIOD_CLK_ENABLE();

  /*Configure GPIO pins : HAT_U_Pin HAT_D_Pin HAT_R_Pin HAT_L_Pin
                           BUTTON_4_Pin BUTTON_5_Pin BUTTON_6_Pin BUTTON_7_Pin
                           BUTTON_8_Pin BUTTON_9_Pin BUTTON_10_Pin BUTTON_11_Pin
                           BUTTON_12_Pin Y_FEED_EN_Pin X_FEED_EN_Pin */
  GPIO_InitStruct.Pin = HAT_U_Pin|HAT_D_Pin|HAT_R_Pin|HAT_L_Pin
                          |BUTTON_4_Pin|BUTTON_5_Pin|BUTTON_6_Pin|BUTTON_7_Pin
                          |BUTTON_8_Pin|BUTTON_9_Pin|BUTTON_10_Pin|BUTTON_11_Pin
                          |BUTTON_12_Pin|Y_FEED_EN_Pin|X_FEED_EN_Pin;
  GPIO_InitStruct.Mode = GPIO_MODE_INPUT;
  GPIO_InitStruct.Pull = GPIO_PULLDOWN;
  HAL_GPIO_Init(GPIOE, &GPIO_InitStruct);

  /*Configure GPIO pins : BUTTON_1_Pin BUTTON_2_Pin BUTTON_21_Pin BUTTON_22_Pin */
  GPIO_InitStruct.Pin = BUTTON_1_Pin|BUTTON_2_Pin|BUTTON_21_Pin|BUTTON_22_Pin;
  GPIO_InitStruct.Mode = GPIO_MODE_INPUT;
  GPIO_InitStruct.Pull = GPIO_PULLDOWN;
  HAL_GPIO_Init(GPIOC, &GPIO_InitStruct);

  /*Configure GPIO pins : BUTTON_3_Pin BUTTON_13_Pin BUTTON_14_Pin BUTTON_15_Pin
                           BUTTON_16_Pin SLIDER_FEED_EN_Pin Z_FEED_EN_Pin */
  GPIO_InitStruct.Pin = BUTTON_3_Pin|BUTTON_13_Pin|BUTTON_14_Pin|BUTTON_15_Pin
                          |BUTTON_16_Pin|SLIDER_FEED_EN_Pin|Z_FEED_EN_Pin;
  GPIO_InitStruct.Mode = GPIO_MODE_INPUT;
  GPIO_InitStruct.Pull = GPIO_PULLDOWN;
  HAL_GPIO_Init(GPIOB, &GPIO_InitStruct);

  /*Configure GPIO pins : BUTTON_17_Pin BUTTON_18_Pin BUTTON_19_Pin BUTTON_20_Pin
                           BUTTON_26_Pin BUTTON_27_Pin BUTTON_28_Pin BUTTON_29_Pin
                           BUTTON_30_Pin BUTTON_31_Pin BUTTON_32_Pin */
  GPIO_InitStruct.Pin = BUTTON_17_Pin|BUTTON_18_Pin|BUTTON_19_Pin|BUTTON_20_Pin
                          |BUTTON_26_Pin|BUTTON_27_Pin|BUTTON_28_Pin|BUTTON_29_Pin
                          |BUTTON_30_Pin|BUTTON_31_Pin|BUTTON_32_Pin;
  GPIO_InitStruct.Mode = GPIO_MODE_INPUT;
  GPIO_InitStruct.Pull = GPIO_PULLDOWN;
  HAL_GPIO_Init(GPIOD, &GPIO_InitStruct);

  /*Configure GPIO pins : BUTTON_23_Pin BUTTON_24_Pin BUTTON_25_Pin */
  GPIO_InitStruct.Pin = BUTTON_23_Pin|BUTTON_24_Pin|BUTTON_25_Pin;
  GPIO_InitStruct.Mode = GPIO_MODE_INPUT;
  GPIO_InitStruct.Pull = GPIO_PULLDOWN;
  HAL_GPIO_Init(GPIOA, &GPIO_InitStruct);

}

void Error_Handler(void)
{
  while(1)
  {
  }
}

/************************ (C) COPYRIGHT STMicroelectronics *****END OF FILE****/
